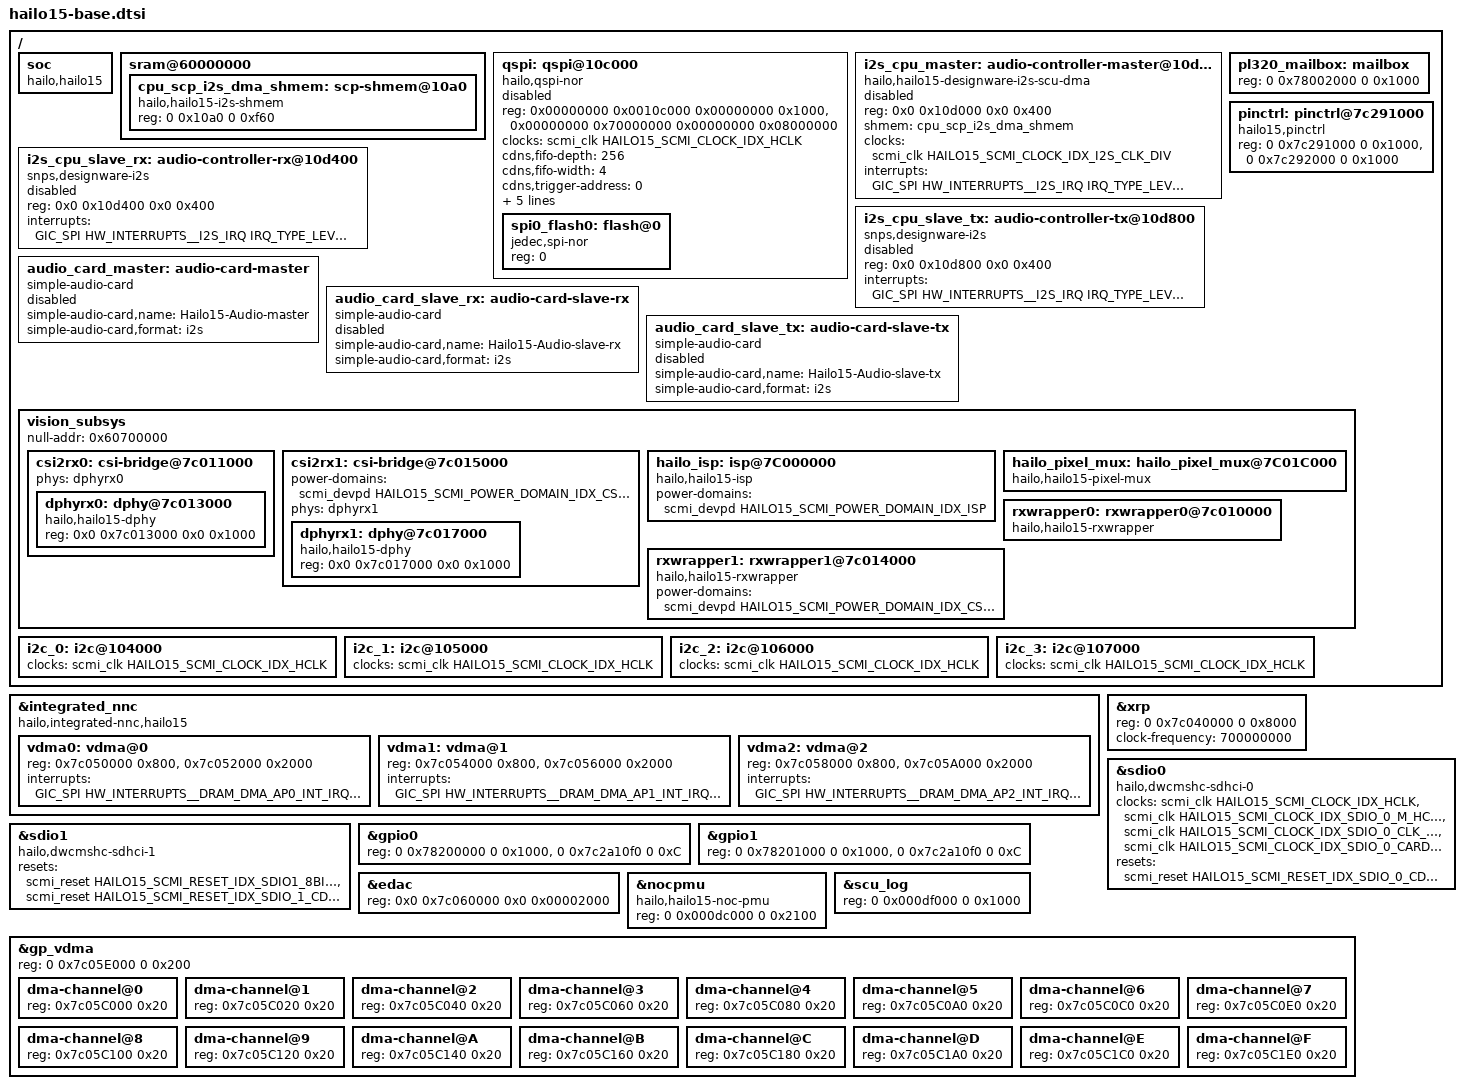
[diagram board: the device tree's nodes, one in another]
// SPDX-License-Identifier:     GPL-2.0
/*
 * Copyright (c) 2019-2024 Hailo Technologies Ltd. All rights reserved.
 */

#define HAILO_SOC_TYPE HAILO_SOC_HAILO15
#include "hailo1x-base.dtsi"


/ {
    soc {
        compatible = "hailo,hailo15";
    };

    sram@60000000 {
        cpu_scp_i2s_dma_shmem: scp-shmem@10a0 {
            compatible = "hailo,hailo15-i2s-shmem";
            reg = <0 0x10a0 0 0xf60>;
        };
    };

    #include "hailo-ethernet.dtsi"
    #include "hailo15-vision.dtsi"
    #include "hailo15-dsp.dtsi"

    qspi: qspi@10c000 {
        compatible = "hailo,qspi-nor";
        #address-cells = <1>;
        #size-cells = <0>;
        reg = <0x00000000 0x0010c000 0x00000000 0x1000>,
                <0x00000000 0x70000000 0x00000000 0x08000000>;
        clocks = <&scmi_clk HAILO15_SCMI_CLOCK_IDX_HCLK>;

        cdns,fifo-depth = <256>;
        cdns,fifo-width = <4>;
        cdns,trigger-address = <0>;
        num-cs = <4>;
        small-fifo-size = <32>;
        cdns,enable-auto-poll;

        interrupts = <GIC_SPI HW_INTERRUPTS__QSPI_FLASH_IRQ IRQ_TYPE_LEVEL_HIGH>;

        status = "disabled";

        spi0_flash0: flash@0 {
            #address-cells = <1>;
            #size-cells = <1>;
            compatible = "jedec,spi-nor";
            reg = <0>; /* chip select */
        };
    };

    i2s_cpu_master: audio-controller-master@10d000 {
        compatible = "hailo,hailo15-designware-i2s-scu-dma";
        reg = <0x0 0x10d000 0x0 0x400>;
        shmem = <&cpu_scp_i2s_dma_shmem>;
        clocks = <&scmi_clk HAILO15_SCMI_CLOCK_IDX_I2S_CLK_DIV>;
        clock-names = "i2sclk";
		#sound-dai-cells = <0>;
        interrupts = <GIC_SPI HW_INTERRUPTS__I2S_IRQ IRQ_TYPE_LEVEL_HIGH>;
        interrupt-names = "i2s_irq";
        status = "disabled";
    };

    i2s_cpu_slave_rx: audio-controller-rx@10d400 {
        compatible = "snps,designware-i2s";
        reg = <0x0 0x10d400 0x0 0x400>;
        #sound-dai-cells = <0>;
        interrupts = <GIC_SPI HW_INTERRUPTS__I2S_IRQ IRQ_TYPE_LEVEL_HIGH>;
        interrupt-names = "i2s_playback_irq";
        status = "disabled";
    };

    i2s_cpu_slave_tx: audio-controller-tx@10d800 {
        compatible = "snps,designware-i2s";
        reg = <0x0 0x10d800 0x0 0x400>;
        #sound-dai-cells = <0>;
        interrupts = <GIC_SPI HW_INTERRUPTS__I2S_IRQ IRQ_TYPE_LEVEL_HIGH>;
        interrupt-names = "i2s_recording_irq";
        status = "disabled";
    };

    audio_card_master: audio-card-master{
        compatible = "simple-audio-card";
        simple-audio-card,name = "Hailo15-Audio-master";
        simple-audio-card,format = "i2s";
        status = "disabled";
    };

    audio_card_slave_rx: audio-card-slave-rx{
        compatible = "simple-audio-card";
        simple-audio-card,name = "Hailo15-Audio-slave-rx";
        simple-audio-card,format = "i2s";
        status = "disabled";
    };

    audio_card_slave_tx: audio-card-slave-tx {
        compatible = "simple-audio-card";
        simple-audio-card,name = "Hailo15-Audio-slave-tx";
        simple-audio-card,format = "i2s";
        status = "disabled";
    };

    pl320_mailbox: mailbox {
        reg = <0 0x78002000 0 0x1000>;
    };

    pinctrl: pinctrl@7c291000 {
        compatible = "hailo15,pinctrl";
        reg = <0 0x7c291000 0 0x1000>,
                <0 0x7c292000 0 0x1000>;
        reg-names = "general_pads_config_base", "gpio_pads_config_base";
    };

    vision_subsys: vision_subsys {
        null-addr = <0x60700000>;

        csi2rx0: csi-bridge@7c011000 {
            phys = <&dphyrx0>;
            phy-names = "dphy";

            dphyrx0: dphy@7c013000 {
                status = "ok";
                reg = <0x0 0x7c013000 0x0 0x1000>;
                compatible = "hailo,hailo15-dphy";
                #phy-cells = <0>;
            };
        };

        csi2rx1: csi-bridge@7c015000 {
            power-domains = <&scmi_devpd HAILO15_SCMI_POWER_DOMAIN_IDX_CSI_RX1>;

            phys = <&dphyrx1>;
            phy-names = "dphy";

            dphyrx1: dphy@7c017000 {
                status = "ok";
                reg = <0x0 0x7c017000 0x0 0x1000>;
                compatible = "hailo,hailo15-dphy";
                #phy-cells = <0>;
            };
        };

        hailo_isp: isp@7C000000 {
            compatible = "hailo,hailo15-isp";
        };

        hailo_pixel_mux: hailo_pixel_mux@7C01C000 {
            compatible = "hailo,hailo15-pixel-mux";
        };

        rxwrapper0: rxwrapper0@7c010000 {
            compatible = "hailo,hailo15-rxwrapper";
        };
    
        rxwrapper1: rxwrapper1@7c014000 {
            power-domains = <&scmi_devpd HAILO15_SCMI_POWER_DOMAIN_IDX_CSI_RX1>;
            compatible = "hailo,hailo15-rxwrapper";
        };
    };

    i2c_0: i2c@104000 {
        clocks = <&scmi_clk HAILO15_SCMI_CLOCK_IDX_HCLK>;
    };

    i2c_1: i2c@105000 {
        clocks = <&scmi_clk HAILO15_SCMI_CLOCK_IDX_HCLK>;
    };

    i2c_2: i2c@106000 {
        clocks = <&scmi_clk HAILO15_SCMI_CLOCK_IDX_HCLK>;
    };

    i2c_3: i2c@107000 {
        clocks = <&scmi_clk HAILO15_SCMI_CLOCK_IDX_HCLK>;
    };
};

&integrated_nnc {
    compatible = "hailo,integrated-nnc,hailo15","hailo,hailort";
    vdma0: vdma@0 {
        reg = <0x7c050000 0x800>, <0x7c052000 0x2000>;
        reg-names = "channel-regs", "engine-regs";
        interrupts = <GIC_SPI HW_INTERRUPTS__DRAM_DMA_AP0_INT_IRQ IRQ_TYPE_LEVEL_HIGH>;
        interrupt-names = "both";
    };

    vdma1: vdma@1 {
        reg = <0x7c054000 0x800>, <0x7c056000 0x2000>;
        reg-names = "channel-regs", "engine-regs";
        interrupts = <GIC_SPI HW_INTERRUPTS__DRAM_DMA_AP1_INT_IRQ IRQ_TYPE_LEVEL_HIGH>;
        interrupt-names = "both";
    };

    vdma2: vdma@2 {
        reg = <0x7c058000 0x800>, <0x7c05A000 0x2000>;
        reg-names = "channel-regs", "engine-regs";
        interrupts = <GIC_SPI HW_INTERRUPTS__DRAM_DMA_AP2_INT_IRQ IRQ_TYPE_LEVEL_HIGH>;
        interrupt-names = "both";
    };
};

&xrp {
    reg = <0 0x7c040000 0 0x8000>; // dsp config
    clock-frequency = <700000000>;
};

&sdio0 {
    compatible = "hailo,dwcmshc-sdhci-0";
    clocks = <&scmi_clk HAILO15_SCMI_CLOCK_IDX_HCLK>, <&scmi_clk HAILO15_SCMI_CLOCK_IDX_SDIO_0_M_HCLK>,
        <&scmi_clk HAILO15_SCMI_CLOCK_IDX_SDIO_0_CLK_DIV_BYPASS>, <&scmi_clk HAILO15_SCMI_CLOCK_IDX_SDIO_0_CARD_CLK>;
    resets = <&scmi_reset HAILO15_SCMI_RESET_IDX_SDIO_0_CD_FROM_PINMUX>;
    clock-names = "core", "bus", "clk_div_bypass","card_clk";
};

&sdio1 {
    compatible = "hailo,dwcmshc-sdhci-1";
    resets = <&scmi_reset HAILO15_SCMI_RESET_IDX_SDIO1_8BIT_MUX>, <&scmi_reset HAILO15_SCMI_RESET_IDX_SDIO_1_CD_FROM_PINMUX>;
    reset-names = "sdio1-8bit-mux", "sdio-cd-input";
};

&gpio0 {
    reg = <0 0x78200000 0 0x1000>,
          <0 0x7c2a10f0 0 0xC>;
};

&gpio1 {
    reg = <0 0x78201000 0 0x1000>,
          <0 0x7c2a10f0 0 0xC>;
};

&hailo_isp {
    power-domains = <&scmi_devpd HAILO15_SCMI_POWER_DOMAIN_IDX_ISP>;
};

&edac {
    reg = <0x0 0x7c060000 0x0 0x00002000>;
};

&nocpmu {
    compatible = "hailo,hailo15-noc-pmu";
    reg = <0 0x000dc000 0 0x2100>;
};

&scu_log {
    reg = <0 0x000df000 0 0x1000>;
};

&gp_vdma {
    reg = <0 0x7c05E000 0 0x200>;
    dma-channel@0 {
        reg = <0x7c05C000 0x20>;
    };
    dma-channel@1 {
        reg = <0x7c05C020 0x20>;
    };
    dma-channel@2 {
        reg = <0x7c05C040 0x20>;
    };
    dma-channel@3 {
        reg = <0x7c05C060 0x20>;
    };
    dma-channel@4 {
        reg = <0x7c05C080 0x20>;
    };
    dma-channel@5 {
        reg = <0x7c05C0A0 0x20>;
    };
    dma-channel@6 {
        reg = <0x7c05C0C0 0x20>;
    };
    dma-channel@7 {
        reg = <0x7c05C0E0 0x20>;
    };
    dma-channel@8 {
        reg = <0x7c05C100 0x20>;
    };
    dma-channel@9 {
        reg = <0x7c05C120 0x20>;
    };
    dma-channel@A {
        reg = <0x7c05C140 0x20>;
    };
    dma-channel@B {
        reg = <0x7c05C160 0x20>;
    };
    dma-channel@C {
        reg = <0x7c05C180 0x20>;
    };
    dma-channel@D {
        reg = <0x7c05C1A0 0x20>;
    };
    dma-channel@E {
        reg = <0x7c05C1C0 0x20>;
    };
    dma-channel@F {
        reg = <0x7c05C1E0 0x20>;
    };
};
